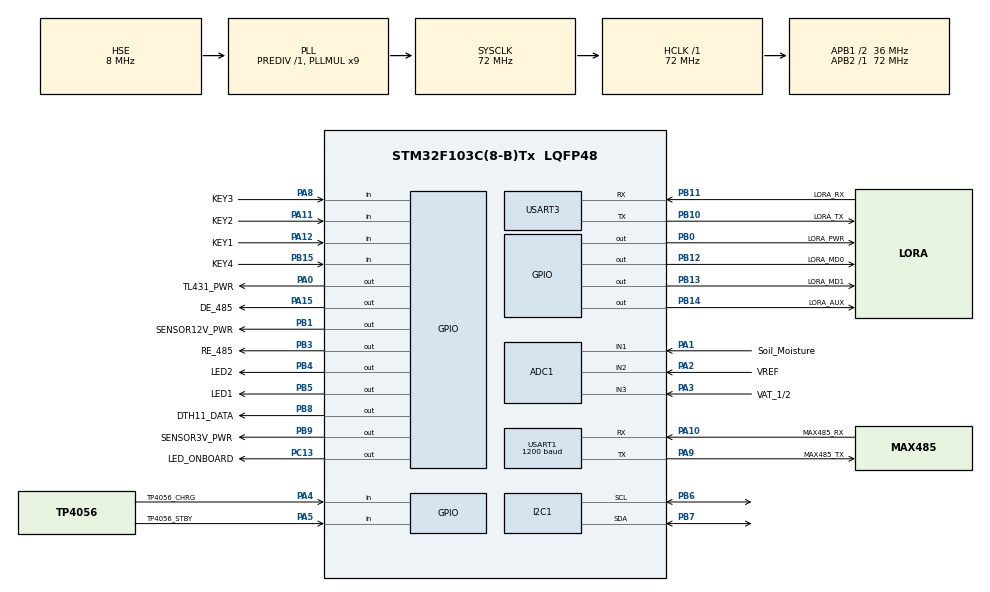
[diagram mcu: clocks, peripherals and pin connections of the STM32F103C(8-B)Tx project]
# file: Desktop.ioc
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ADC1.Channel-2\#ChannelRegularConversion=ADC_CHANNEL_1
ADC1.NbrOfConversionFlag=1
ADC1.Rank-2\#ChannelRegularConversion=1
ADC1.SamplingTime-2\#ChannelRegularConversion=ADC_SAMPLETIME_1CYCLE_5
ADC1.master=1
Mcu.Family=STM32F1
Mcu.Name=STM32F103C(8-B)Tx
Mcu.Package=LQFP48
NVIC.PriorityGroup=NVIC_PRIORITYGROUP_4
PA0-WKUP.GPIO_Label=TL431_PWR
PA0-WKUP.PinState=GPIO_PIN_SET
PA0-WKUP.Signal=GPIO_Output
PA1.GPIO_Label=Soil_Moisture
PA1.Signal=ADCx_IN1
PA10.GPIO_Label=MAX485_RX
PA10.Mode=Asynchronous
PA10.Signal=USART1_RX
PA11.GPIO_Label=KEY2
PA11.GPIO_PuPd=GPIO_PULLUP
PA11.Signal=GPIO_Input
PA12.GPIO_Label=KEY1
PA12.GPIO_PuPd=GPIO_PULLUP
PA12.Signal=GPIO_Input
PA13.Mode=Serial_Wire
PA13.Signal=SYS_JTMS-SWDIO
PA14.Mode=Serial_Wire
PA14.Signal=SYS_JTCK-SWCLK
PA15.GPIO_Label=DE_485
PA15.PinState=GPIO_PIN_SET
PA15.Signal=GPIO_Output
PA2.GPIO_Label=VREF
PA2.Signal=ADCx_IN2
PA3.GPIO_Label=VAT_1/2
PA3.Signal=ADCx_IN3
PA4.GPIO_Label=TP4056_CHRG
PA4.GPIO_PuPd=GPIO_PULLUP
PA4.Signal=GPIO_Input
PA5.GPIO_Label=TP4056_STBY
PA5.GPIO_PuPd=GPIO_PULLUP
PA5.Signal=GPIO_Input
PA8.GPIO_Label=KEY3
PA8.GPIO_PuPd=GPIO_PULLUP
PA8.Signal=GPIO_Input
PA9.GPIO_Label=MAX485_TX
PA9.Mode=Asynchronous
PA9.Signal=USART1_TX
PB0.GPIO_Label=LORA_PWR
PB0.PinState=GPIO_PIN_SET
PB0.Signal=GPIO_Output
PB1.GPIO_Label=SENSOR12V_PWR
PB1.PinState=GPIO_PIN_SET
PB1.Signal=GPIO_Output
PB10.GPIO_Label=LORA_TX
PB10.Mode=Asynchronous
PB10.Signal=USART3_TX
PB11.GPIO_Label=LORA_RX
PB11.Mode=Asynchronous
PB11.Signal=USART3_RX
PB12.GPIO_Label=LORA_MD0
PB12.PinState=GPIO_PIN_SET
PB12.Signal=GPIO_Output
PB13.GPIO_Label=LORA_MD1
PB13.PinState=GPIO_PIN_SET
PB13.Signal=GPIO_Output
PB14.GPIO_Label=LORA_AUX
PB14.PinState=GPIO_PIN_SET
PB14.Signal=GPIO_Output
PB15.GPIO_Label=KEY4
PB15.GPIO_PuPd=GPIO_PULLUP
PB15.Signal=GPIO_Input
PB3.GPIO_Label=RE_485
PB3.PinState=GPIO_PIN_SET
PB3.Signal=GPIO_Output
PB4.GPIO_Label=LED2
PB4.PinState=GPIO_PIN_SET
PB4.Signal=GPIO_Output
PB5.GPIO_Label=LED1
PB5.PinState=GPIO_PIN_SET
PB5.Signal=GPIO_Output
PB6.Mode=I2C
PB6.Signal=I2C1_SCL
PB7.Mode=I2C
PB7.Signal=I2C1_SDA
PB8.GPIO_Label=DTH11_DATA
PB8.GPIO_Speed=GPIO_SPEED_FREQ_MEDIUM
PB8.PinState=GPIO_PIN_SET
PB8.Signal=GPIO_Output
PB9.GPIO_Label=SENSOR3V_PWR
PB9.PinState=GPIO_PIN_SET
PB9.Signal=GPIO_Output
PC13-TAMPER-RTC.GPIO_Label=LED_ONBOARD
PC13-TAMPER-RTC.PinState=GPIO_PIN_SET
PC13-TAMPER-RTC.Signal=GPIO_Output
PC14-OSC32_IN.Mode=LSE-External-Oscillator
PC14-OSC32_IN.Signal=RCC_OSC32_IN
PC15-OSC32_OUT.Mode=LSE-External-Oscillator
PC15-OSC32_OUT.Signal=RCC_OSC32_OUT
PD0-OSC_IN.Mode=HSE-External-Oscillator
PD0-OSC_IN.Signal=RCC_OSC_IN
PD1-OSC_OUT.Mode=HSE-External-Oscillator
PD1-OSC_OUT.Signal=RCC_OSC_OUT
ProjectManager.HeapSize=0x200
ProjectManager.StackSize=0x400
ProjectManager.TargetToolchain=MDK-ARM V5.27
RCC.ADCPresc=RCC_ADCPCLK2_DIV6
RCC.AHBFreq_Value=72000000
RCC.APB1CLKDivider=RCC_HCLK_DIV2
RCC.APB1Freq_Value=36000000
RCC.APB1TimFreq_Value=72000000
RCC.APB2Freq_Value=72000000
RCC.APB2TimFreq_Value=72000000
RCC.HCLKFreq_Value=72000000
RCC.PLLMUL=RCC_PLL_MUL9
RCC.PLLSourceVirtual=RCC_PLLSOURCE_HSE
RCC.SYSCLKFreq_VALUE=72000000
RCC.SYSCLKSource=RCC_SYSCLKSOURCE_PLLCLK
RCC.USBFreq_Value=72000000
SH.ADCx_IN1.0=ADC1_IN1,IN1
SH.ADCx_IN2.0=ADC1_IN2,IN2
SH.ADCx_IN3.0=ADC1_IN3,IN3
USART1.BaudRate=1200
USART1.VirtualMode=VM_ASYNC
USART3.VirtualMode=VM_ASYNC
board=custom

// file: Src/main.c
/* USER CODE BEGIN Header */
/**
  ******************************************************************************
  * @file           : main.c
  * @brief          : Main program body
  ******************************************************************************
  * @attention
  *
  * <h2><center>&copy; Copyright (c) 2019 STMicroelectronics.
  * All rights reserved.</center></h2>
  *
  * This software component is licensed by ST under BSD 3-Clause license,
  * the "License"; You may not use this file except in compliance with the
  * License. You may obtain a copy of the License at:
  *                        opensource.org/licenses/BSD-3-Clause
  *
  ******************************************************************************
  */
/* USER CODE END Header */

#include "main.h"
#include "adc.h"
#include "i2c.h"
#include "usart.h"
#include "gpio.h"

void SystemClock_Config(void);

int main(void)
{

  /* MCU Configuration--------------------------------------------------------*/

  /* Reset of all peripherals, Initializes the Flash interface and the Systick. */
  HAL_Init();

  /* Configure the system clock */
  SystemClock_Config();

  /* Initialize all configured peripherals */
  MX_GPIO_Init();
  MX_ADC1_Init();
  MX_I2C1_Init();
  MX_USART1_UART_Init();
  MX_USART3_UART_Init();

  /* Infinite loop */
  /* USER CODE BEGIN WHILE */
  while (1)
  {
//    HAL_GPIO_TogglePin(LED_ONBOARD_GPIO_Port,LED_ONBOARD_Pin);
		HAL_GPIO_TogglePin(LED1_GPIO_Port,LED1_Pin);
		HAL_GPIO_TogglePin(LED2_GPIO_Port,LED2_Pin);
		HAL_GPIO_TogglePin(LORA_PWR_GPIO_Port,LORA_PWR_Pin);
		HAL_Delay(100);
		HAL_GPIO_TogglePin(SENSOR12V_PWR_GPIO_Port,SENSOR12V_PWR_Pin);
		HAL_Delay(100);
		HAL_GPIO_TogglePin(SENSOR3V_PWR_GPIO_Port,SENSOR3V_PWR_Pin);
		HAL_Delay(100);
		HAL_UART_Transmit(&huart3,(uint8_t*)"fuck",sizeof("fuck") - 1,1000);
		HAL_UART_Transmit(&huart1,(uint8_t*)"fuck",sizeof("fuck") - 1,1000);
		HAL_Delay(700);
//		HAL_PWR_EnterSTOPMode(PWR_LOWPOWERREGULATOR_ON,PWR_STOPENTRY_WFI);
//		while(1);

    /* USER CODE END WHILE */

  }
}

void SystemClock_Config(void)
{
  RCC_OscInitTypeDef RCC_OscInitStruct = {0};
  RCC_ClkInitTypeDef RCC_ClkInitStruct = {0};
  RCC_PeriphCLKInitTypeDef PeriphClkInit = {0};

  /** Initializes the CPU, AHB and APB busses clocks
  */
  RCC_OscInitStruct.OscillatorType = RCC_OSCILLATORTYPE_HSE;
  RCC_OscInitStruct.HSEState = RCC_HSE_ON;
  RCC_OscInitStruct.HSEPredivValue = RCC_HSE_PREDIV_DIV1;
  RCC_OscInitStruct.HSIState = RCC_HSI_ON;
  RCC_OscInitStruct.PLL.PLLState = RCC_PLL_ON;
  RCC_OscInitStruct.PLL.PLLSource = RCC_PLLSOURCE_HSE;
  RCC_OscInitStruct.PLL.PLLMUL = RCC_PLL_MUL9;
  if (HAL_RCC_OscConfig(&RCC_OscInitStruct) != HAL_OK)
  {
    Error_Handler();
  }
  /** Initializes the CPU, AHB and APB busses clocks
  */
  RCC_ClkInitStruct.ClockType = RCC_CLOCKTYPE_HCLK|RCC_CLOCKTYPE_SYSCLK
                              |RCC_CLOCKTYPE_PCLK1|RCC_CLOCKTYPE_PCLK2;
  RCC_ClkInitStruct.SYSCLKSource = RCC_SYSCLKSOURCE_PLLCLK;
  RCC_ClkInitStruct.AHBCLKDivider = RCC_SYSCLK_DIV1;
  RCC_ClkInitStruct.APB1CLKDivider = RCC_HCLK_DIV2;
  RCC_ClkInitStruct.APB2CLKDivider = RCC_HCLK_DIV1;

  if (HAL_RCC_ClockConfig(&RCC_ClkInitStruct, FLASH_LATENCY_2) != HAL_OK)
  {
    Error_Handler();
  }
  PeriphClkInit.PeriphClockSelection = RCC_PERIPHCLK_ADC;
  PeriphClkInit.AdcClockSelection = RCC_ADCPCLK2_DIV6;
  if (HAL_RCCEx_PeriphCLKConfig(&PeriphClkInit) != HAL_OK)
  {
    Error_Handler();
  }
}

void Error_Handler(void)
{
}

/************************ (C) COPYRIGHT STMicroelectronics *****END OF FILE****/
